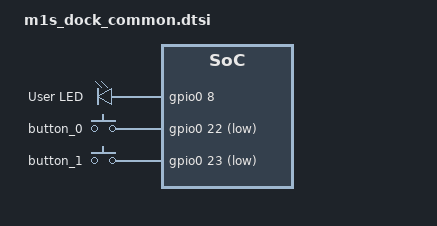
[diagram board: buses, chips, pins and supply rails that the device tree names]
/*
 * Copyright The Zephyr Project Contributors
 *
 * SPDX-License-Identifier: Apache-2.0
 */

#include "m1s_dock-pinctrl.dtsi"
#include <zephyr/dt-bindings/input/input-event-codes.h>
#include <zephyr/dt-bindings/pwm/pwm.h>

/ {
	aliases {
		led0 = &user_led0;
		sw0 = &button_0;
	};

	leds {
		compatible = "gpio-leds";

		user_led0: led_0 {
			gpios = <&gpio0 8 GPIO_ACTIVE_HIGH>;
			label = "User LED";
		};
	};

	buttons {
		compatible = "gpio-keys";

		button_0: sw0 {
			gpios = <&gpio0 22 GPIO_ACTIVE_LOW>;
			zephyr,code = <INPUT_KEY_0>;
		};

		button_1: sw1 {
			gpios = <&gpio0 23 GPIO_ACTIVE_LOW>;
			zephyr,code = <INPUT_KEY_1>;
		};
	};
};
